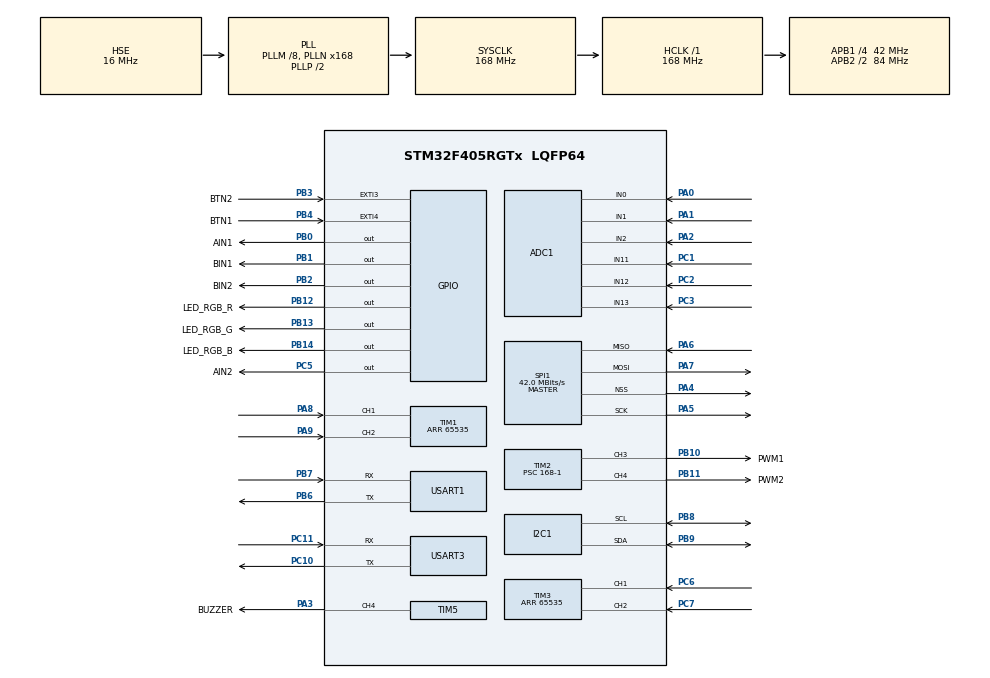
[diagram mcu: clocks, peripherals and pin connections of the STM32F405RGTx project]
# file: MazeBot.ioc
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ADC1.Channel-1\#ChannelRegularConversion=ADC_CHANNEL_0
ADC1.ContinuousConvMode=ENABLE
ADC1.DMAContinuousRequests=DISABLE
ADC1.NbrOfConversion=1
ADC1.NbrOfConversionFlag=1
ADC1.Rank-1\#ChannelRegularConversion=1
ADC1.SamplingTime-1\#ChannelRegularConversion=ADC_SAMPLETIME_3CYCLES
ADC1.ScanConvMode=ENABLE
ADC1.master=1
FREERTOS.Tasks01=defaultTask,0,128,StartDefaultTask,Default,NULL,Dynamic,NULL,NULL;insTask,0,256,InsTask,As weak,NULL,Dynamic,NULL,NULL;navigationTask,0,256,NavigationTask,As weak,NULL,Dynamic,NULL,NULL;chassisTask,0,256,ChassisTask,As weak,NULL,Dynamic,NULL,NULL;displayTask,0,128,DisplayTask,As weak,NULL,Dynamic,NULL,NULL;wifiTak,0,256,WifiTask,As weak,NULL,Dynamic,NULL,NULL
Mcu.Family=STM32F4
Mcu.Name=STM32F405RGTx
Mcu.Package=LQFP64
NVIC.PriorityGroup=NVIC_PRIORITYGROUP_4
NVIC.TIM1_UP_TIM10_IRQn=true\:0\:0\:false\:false\:true\:false\:false\:true
NVIC.TimeBase=TIM1_UP_TIM10_IRQn
NVIC.TimeBaseIP=TIM10
NVIC.USART1_IRQn=true\:5\:0\:false\:false\:true\:true\:true\:true
NVIC.USART3_IRQn=true\:5\:0\:false\:false\:true\:true\:true\:true
PA0-WKUP.GPIO_PuPd=GPIO_NOPULL
PA0-WKUP.Signal=ADCx_IN0
PA1.Signal=ADCx_IN1
PA13.Mode=Serial_Wire
PA13.Signal=SYS_JTMS-SWDIO
PA14.Mode=Serial_Wire
PA14.Signal=SYS_JTCK-SWCLK
PA2.Signal=ADCx_IN2
PA3.GPIO_Label=BUZZER
PA3.GPIO_PuPd=GPIO_PULLUP
PA3.Signal=S_TIM5_CH4
PA4.Mode=NSS_Signal_Hard_Output
PA4.Signal=SPI1_NSS
PA5.Mode=Full_Duplex_Master
PA5.Signal=SPI1_SCK
PA6.Mode=Full_Duplex_Master
PA6.Signal=SPI1_MISO
PA7.Mode=Full_Duplex_Master
PA7.Signal=SPI1_MOSI
PA8.GPIO_PuPd=GPIO_PULLUP
PA8.Signal=S_TIM1_CH1
PA9.GPIO_PuPd=GPIO_PULLUP
PA9.Signal=S_TIM1_CH2
PB0.GPIO_Label=AIN1
PB0.Signal=GPIO_Output
PB1.GPIO_Label=BIN1
PB1.Signal=GPIO_Output
PB10.GPIO_Label=PWM1
PB10.GPIO_PuPd=GPIO_NOPULL
PB10.GPIO_Speed=GPIO_SPEED_FREQ_VERY_HIGH
PB10.Signal=S_TIM2_CH3
PB11.GPIO_Label=PWM2
PB11.GPIO_Speed=GPIO_SPEED_FREQ_VERY_HIGH
PB11.Signal=S_TIM2_CH4
PB12.GPIO_Label=LED_RGB_R
PB12.GPIO_PuPd=GPIO_PULLUP
PB12.PinState=GPIO_PIN_RESET
PB12.Signal=GPIO_Output
PB13.GPIO_Label=LED_RGB_G
PB13.GPIO_PuPd=GPIO_PULLUP
PB13.PinState=GPIO_PIN_RESET
PB13.Signal=GPIO_Output
PB14.GPIO_Label=LED_RGB_B
PB14.GPIO_PuPd=GPIO_PULLUP
PB14.PinState=GPIO_PIN_RESET
PB14.Signal=GPIO_Output
PB2.GPIO_Label=BIN2
PB2.Signal=GPIO_Output
PB3.GPIO_Label=BTN2
PB3.GPIO_PuPd=GPIO_PULLUP
PB3.Signal=GPXTI3
PB4.GPIO_Label=BTN1
PB4.GPIO_PuPd=GPIO_PULLUP
PB4.Signal=GPXTI4
PB6.Mode=Asynchronous
PB6.Signal=USART1_TX
PB7.Mode=Asynchronous
PB7.Signal=USART1_RX
PB8.Mode=I2C
PB8.Signal=I2C1_SCL
PB9.Mode=I2C
PB9.Signal=I2C1_SDA
PC1.Signal=ADCx_IN11
PC10.Mode=Asynchronous
PC10.Signal=USART3_TX
PC11.Mode=Asynchronous
PC11.Signal=USART3_RX
PC2.Signal=ADCx_IN12
PC3.Signal=ADCx_IN13
PC5.GPIO_Label=AIN2
PC5.Signal=GPIO_Output
PC6.Signal=S_TIM3_CH1
PC7.Signal=S_TIM3_CH2
PH0-OSC_IN.Mode=HSE-External-Oscillator
PH0-OSC_IN.Signal=RCC_OSC_IN
PH1-OSC_OUT.Mode=HSE-External-Oscillator
PH1-OSC_OUT.Signal=RCC_OSC_OUT
ProjectManager.HeapSize=0x200
ProjectManager.StackSize=0x400
ProjectManager.TargetToolchain=MDK-ARM V5.27
RCC.48MHZClocksFreq_Value=84000000
RCC.AHBFreq_Value=168000000
RCC.APB1CLKDivider=RCC_HCLK_DIV4
RCC.APB1Freq_Value=42000000
RCC.APB1TimFreq_Value=84000000
RCC.APB2CLKDivider=RCC_HCLK_DIV2
RCC.APB2Freq_Value=84000000
RCC.APB2TimFreq_Value=168000000
RCC.CortexFreq_Value=168000000
RCC.HCLKFreq_Value=168000000
RCC.HSE_VALUE=16000000
RCC.HSI_VALUE=16000000
RCC.LSE_VALUE=32768
RCC.PLLM=8
RCC.PLLN=168
RCC.PLLSourceVirtual=RCC_PLLSOURCE_HSE
RCC.SYSCLKFreq_VALUE=168000000
RCC.SYSCLKSource=RCC_SYSCLKSOURCE_PLLCLK
RCC.VCOOutputFreq_Value=336000000
SH.ADCx_IN0.0=ADC1_IN0,IN0
SH.ADCx_IN1.0=ADC1_IN1,IN1
SH.ADCx_IN11.0=ADC1_IN11,IN11
SH.ADCx_IN12.0=ADC1_IN12,IN12
SH.ADCx_IN13.0=ADC1_IN13,IN13
SH.ADCx_IN2.0=ADC1_IN2,IN2
SH.S_TIM1_CH1.0=TIM1_CH1,Encoder_Interface
SH.S_TIM1_CH2.0=TIM1_CH2,Encoder_Interface
SH.S_TIM2_CH3.0=TIM2_CH3,PWM Generation3 CH3
SH.S_TIM2_CH4.0=TIM2_CH4,PWM Generation4 CH4
SH.S_TIM3_CH1.0=TIM3_CH1,Encoder_Interface
SH.S_TIM3_CH2.0=TIM3_CH2,Encoder_Interface
SH.S_TIM5_CH4.0=TIM5_CH4,PWM Generation4 CH4
SPI1.CalculateBaudRate=42.0 MBits/s
SPI1.Direction=SPI_DIRECTION_2LINES
SPI1.Mode=SPI_MODE_MASTER
SPI1.VirtualNSS=VM_NSSHARD
SPI1.VirtualType=VM_MASTER
TIM1.EncoderMode=TIM_ENCODERMODE_TI12
TIM1.Period=65535
TIM2.Channel-PWM\ Generation3\ CH3=TIM_CHANNEL_3
TIM2.Channel-PWM\ Generation4\ CH4=TIM_CHANNEL_4
TIM2.Period=1000-1
TIM2.Prescaler=168-1
TIM3.EncoderMode=TIM_ENCODERMODE_TI12
TIM3.Period=65535
TIM5.Channel-PWM\ Generation4\ CH4=TIM_CHANNEL_4
TIM5.Period=500-1
TIM5.Prescaler=168-1
TIM5.Pulse-PWM\ Generation4\ CH4=250
TIM6.Period=5000-1
TIM6.Prescaler=168-1
USART1.VirtualMode=VM_ASYNC
USART3.VirtualMode=VM_ASYNC
VP_FREERTOS_VS_CMSIS_V1.Mode=CMSIS_V1
VP_SYS_VS_tim10.Mode=TIM10
VP_TIM6_VS_ClockSourceINT.Mode=Enable_Timer
board=custom

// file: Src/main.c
/* USER CODE BEGIN Header */
/**
  ******************************************************************************
  * @file           : main.c
  * @brief          : Main program body
  ******************************************************************************
  * @attention
  *
  * <h2><center>&copy; Copyright (c) 2020 STMicroelectronics.
  * All rights reserved.</center></h2>
  *
  * This software component is licensed by ST under BSD 3-Clause license,
  * the "License"; You may not use this file except in compliance with the
  * License. You may obtain a copy of the License at:
  *                        opensource.org/licenses/BSD-3-Clause
  *
  ******************************************************************************
  */
/* USER CODE END Header */

#include "main.h"
#include "cmsis_os.h"
#include "adc.h"
#include "i2c.h"
#include "spi.h"
#include "tim.h"
#include "usart.h"
#include "gpio.h"

/* USER CODE BEGIN Includes */
#include "Wifi.h"
#include "WifiConfig.h"
#include "movebase.h"
/* USER CODE END Includes */

/* USER CODE BEGIN PD */
//typedef union _adc_data
//{
//  uint8_t data[16];
//  float ActVal[4];
//} adcdata_def;
/* USER CODE END PD */

/* USER CODE BEGIN PV */
//float ADC_Value_Temp[6];
//adcdata_def ADC_Value;
/* USER CODE END PV */

void SystemClock_Config(void);
void MX_FREERTOS_Init(void);

int main(void)
{

  /* MCU Configuration--------------------------------------------------------*/

  /* Reset of all peripherals, Initializes the Flash interface and the Systick. */
  HAL_Init();

  /* Configure the system clock */
  SystemClock_Config();

  /* Initialize all configured peripherals */
  MX_GPIO_Init();
  MX_ADC1_Init();
  MX_I2C1_Init();
  MX_SPI1_Init();
  MX_TIM1_Init();
  MX_TIM2_Init();
  MX_TIM3_Init();
  MX_USART3_UART_Init();
  MX_TIM6_Init();
  MX_TIM5_Init();
  MX_USART1_UART_Init();
  /* USER CODE BEGIN 2 */
  printf("*** MazeBot Init! *** \r\n");

  HAL_TIM_Encoder_Start(&MOTOR0_TIM, TIM_CHANNEL_ALL);
  HAL_TIM_Encoder_Start(&MOTOR1_TIM, TIM_CHANNEL_ALL);

  HAL_TIM_PWM_Start(&MOTOR_PWM_TIM, MOTOR0_PWM_TIM_CHANNEL);
  HAL_TIM_PWM_Start(&MOTOR_PWM_TIM, MOTOR1_PWM_TIM_CHANNEL);

	//HAL_ADCEx_Calibration_Start(&hadc1); //ADC校准

	//开启ADC DMA传输 400个数据一个循环，一路采集100个数据，做滤波
//  HAL_ADC_Start_DMA(&hadc1, (uint32_t*)&ADC_Value_Temp, 60);

  //	HAL_TIM_PWM_Start(&BUZZER_TIM, BUZZER_TIM_CHANNEL);
  //
  //	__HAL_TIM_SET_AUTORELOAD(&BUZZER_TIM, 2000);

  //	__HAL_TIM_SET_COMPARE(&BUZZER_TIM, BUZZER_TIM_CHANNEL, 1000);

  /* USER CODE END 2 */

  /* Call init function for freertos objects (in freertos.c) */
  MX_FREERTOS_Init();

  /* Start scheduler */
  osKernelStart();

  /* We should never get here as control is now taken by the scheduler */

  /* Infinite loop */
  while (1)
  {

  }
}

void SystemClock_Config(void)
{
  RCC_OscInitTypeDef RCC_OscInitStruct = {0};
  RCC_ClkInitTypeDef RCC_ClkInitStruct = {0};

  /** Configure the main internal regulator output voltage
  */
  __HAL_RCC_PWR_CLK_ENABLE();
  __HAL_PWR_VOLTAGESCALING_CONFIG(PWR_REGULATOR_VOLTAGE_SCALE1);
  /** Initializes the CPU, AHB and APB busses clocks
  */
  RCC_OscInitStruct.OscillatorType = RCC_OSCILLATORTYPE_HSE;
  RCC_OscInitStruct.HSEState = RCC_HSE_ON;
  RCC_OscInitStruct.PLL.PLLState = RCC_PLL_ON;
  RCC_OscInitStruct.PLL.PLLSource = RCC_PLLSOURCE_HSE;
  RCC_OscInitStruct.PLL.PLLM = 8;
  RCC_OscInitStruct.PLL.PLLN = 168;
  RCC_OscInitStruct.PLL.PLLP = RCC_PLLP_DIV2;
  RCC_OscInitStruct.PLL.PLLQ = 4;
  if (HAL_RCC_OscConfig(&RCC_OscInitStruct) != HAL_OK)
  {
    Error_Handler();
  }
  /** Initializes the CPU, AHB and APB busses clocks
  */
  RCC_ClkInitStruct.ClockType = RCC_CLOCKTYPE_HCLK|RCC_CLOCKTYPE_SYSCLK
                              |RCC_CLOCKTYPE_PCLK1|RCC_CLOCKTYPE_PCLK2;
  RCC_ClkInitStruct.SYSCLKSource = RCC_SYSCLKSOURCE_PLLCLK;
  RCC_ClkInitStruct.AHBCLKDivider = RCC_SYSCLK_DIV1;
  RCC_ClkInitStruct.APB1CLKDivider = RCC_HCLK_DIV4;
  RCC_ClkInitStruct.APB2CLKDivider = RCC_HCLK_DIV2;

  if (HAL_RCC_ClockConfig(&RCC_ClkInitStruct, FLASH_LATENCY_5) != HAL_OK)
  {
    Error_Handler();
  }
}

void HAL_TIM_PeriodElapsedCallback(TIM_HandleTypeDef *htim)
{
  if (htim->Instance == TIM10) {
    HAL_IncTick();
  }
}

void Error_Handler(void)
{
}

/************************ (C) COPYRIGHT STMicroelectronics *****END OF FILE****/

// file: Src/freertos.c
/* USER CODE BEGIN Header */
/**
  ******************************************************************************
  * File Name          : freertos.c
  * Description        : Code for freertos applications
  ******************************************************************************
  * @attention
  *
  * <h2><center>&copy; Copyright (c) 2020 STMicroelectronics.
  * All rights reserved.</center></h2>
  *
  * This software component is licensed by ST under Ultimate Liberty license
  * SLA0044, the "License"; You may not use this file except in compliance with
  * the License. You may obtain a copy of the License at:
  *                             www.st.com/SLA0044
  *
  ******************************************************************************
  */
/* USER CODE END Header */

#include "FreeRTOS.h"
#include "task.h"
#include "main.h"
#include "cmsis_os.h"

/* USER CODE BEGIN Includes */
#include "bsp_led.h"
#include "ssd1306_tests.h"
/* USER CODE END Includes */

osThreadId defaultTaskHandle;
osThreadId insTaskHandle;
osThreadId navigationTaskHandle;
osThreadId chassisTaskHandle;
osThreadId displayTaskHandle;
osThreadId wifiTakHandle;

void StartDefaultTask(void const * argument);
void InsTask(void const * argument);
void NavigationTask(void const * argument);
void ChassisTask(void const * argument);
void DisplayTask(void const * argument);
void WifiTask(void const * argument);

void MX_FREERTOS_Init(void); /* (MISRA C 2004 rule 8.1) */

/* GetIdleTaskMemory prototype (linked to static allocation support) */
void vApplicationGetIdleTaskMemory( StaticTask_t **ppxIdleTaskTCBBuffer, StackType_t **ppxIdleTaskStackBuffer, uint32_t *pulIdleTaskStackSize );

/* USER CODE BEGIN GET_IDLE_TASK_MEMORY */
static StaticTask_t xIdleTaskTCBBuffer;
static StackType_t xIdleStack[configMINIMAL_STACK_SIZE];

void vApplicationGetIdleTaskMemory( StaticTask_t **ppxIdleTaskTCBBuffer, StackType_t **ppxIdleTaskStackBuffer, uint32_t *pulIdleTaskStackSize )
{
  *ppxIdleTaskTCBBuffer = &xIdleTaskTCBBuffer;
  *ppxIdleTaskStackBuffer = &xIdleStack[0];
  *pulIdleTaskStackSize = configMINIMAL_STACK_SIZE;
  /* place for user code */
}
/* USER CODE END GET_IDLE_TASK_MEMORY */

void MX_FREERTOS_Init(void) {

  /* Create the thread(s) */
  /* definition and creation of defaultTask */
  osThreadDef(defaultTask, StartDefaultTask, osPriorityNormal, 0, 128);
  defaultTaskHandle = osThreadCreate(osThread(defaultTask), NULL);

  /* definition and creation of insTask */
  osThreadDef(insTask, InsTask, osPriorityNormal, 0, 256);
  insTaskHandle = osThreadCreate(osThread(insTask), NULL);

  /* definition and creation of navigationTask */
  osThreadDef(navigationTask, NavigationTask, osPriorityNormal, 0, 256);
  navigationTaskHandle = osThreadCreate(osThread(navigationTask), NULL);

  /* definition and creation of chassisTask */
  osThreadDef(chassisTask, ChassisTask, osPriorityNormal, 0, 256);
  chassisTaskHandle = osThreadCreate(osThread(chassisTask), NULL);

  /* definition and creation of displayTask */
  osThreadDef(displayTask, DisplayTask, osPriorityNormal, 0, 128);
  displayTaskHandle = osThreadCreate(osThread(displayTask), NULL);

  /* definition and creation of wifiTak */
  osThreadDef(wifiTak, WifiTask, osPriorityNormal, 0, 256);
  wifiTakHandle = osThreadCreate(osThread(wifiTak), NULL);

}

void StartDefaultTask(void const * argument)
{
  /* USER CODE BEGIN StartDefaultTask */

  /* Infinite loop */
  for(;;)
  {
		//ssd1306_TestAll();

  }
  /* USER CODE END StartDefaultTask */
}

__weak void InsTask(void const * argument)
{
  for(;;)
  {
    osDelay(1);
  }
}

__weak void NavigationTask(void const * argument)
{
  for(;;)
  {
    osDelay(1);
  }
}

__weak void ChassisTask(void const * argument)
{
  for(;;)
  {
    osDelay(1);
  }
}

__weak void DisplayTask(void const * argument)
{
  for(;;)
  {
    osDelay(1);
  }
}

__weak void WifiTask(void const * argument)
{
  for(;;)
  {
    osDelay(1);
  }
}

/************************ (C) COPYRIGHT STMicroelectronics *****END OF FILE****/
